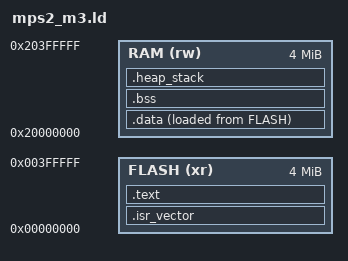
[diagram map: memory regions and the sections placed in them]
MEMORY
{
    FLASH (xr) : ORIGIN = 0x00000000, LENGTH = 4M
    RAM   (rw) : ORIGIN = 0x20000000, LENGTH = 4M
}

ENTRY(Reset_Handler)

_Min_Stack_Size = 0x400;
_estack = ORIGIN(RAM) + LENGTH(RAM);

SECTIONS
{
    .isr_vector :
    {
        __vector_table = .;
        KEEP(*(.isr_vector))
        . = ALIGN(4);
    } > FLASH

    .text :
    {
        *(.text*)
        *(.rodata*)
        *(.constdata*)
        . = ALIGN(4);
        _etext = .;
        _sidata = .;
    } > FLASH

    .data :
    {
        . = ALIGN(8);
        _sdata = .;
        *(.data*)
        . = ALIGN(8);
        _edata = .;
    } > RAM AT > FLASH

    .bss :
    {
        . = ALIGN(8);
        _sbss = .;
        *(.bss*)
        *(COMMON)
        . = ALIGN(8);
        _ebss = .;
    } > RAM

    .heap_stack :
    {
        . = ALIGN(8);
        PROVIDE(end = .);
        PROVIDE(_end = .);
        . = . + _Min_Stack_Size;
        . = ALIGN(8);
    } > RAM

    __StackTop   = ORIGIN(RAM) + LENGTH(RAM);
    __StackLimit = __StackTop - _Min_Stack_Size;
    PROVIDE(__stack = __StackTop);

    ASSERT(__StackLimit >= _ebss, "region RAM overflowed with stack")
}
